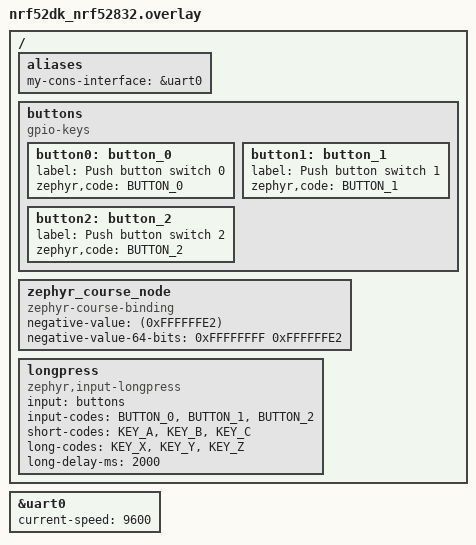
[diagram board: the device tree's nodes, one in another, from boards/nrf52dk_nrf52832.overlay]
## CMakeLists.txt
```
add_subdirectory(
    ${CMAKE_CURRENT_LIST_DIR}/modules/hal_nordic/nrfx
    ${CMAKE_CURRENT_BINARY_DIR}/zephyr_course_nrfx
)

zephyr_syscall_header(${ZEPHYR_MYCOURSEMODULE_MODULE_DIR}/include/blinker.h)

zephyr_library()

zephyr_library_sources(drivers/blinker.c)
zephyr_include_directories(${ZEPHYR_MYCOURSEMODULE_MODULE_DIR}/include)
```

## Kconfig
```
source "Kconfig.zephyr"

menu "Custom Application Configuration"
    
module = ZEPHYR_COURSE
module-str = zephyr_course
source "subsys/logging/Kconfig.template.log_config"

config BOARD
    string # Is invisible since we dont define a prompt
    default "zephyr_course_board"
    help
      Set a custom board name. This value will override the default board name.
config UART_DEVICE_STATUS
    string "UART Status"
    # bool "UART Status"
    # default $(dt_node_str_prop_equals,/soc/uart@40002000,status,okay)
    default $(dt_alias_enabled,my-cons-interface)
    help
      UART device status.

endmenu
```

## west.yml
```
manifest:
  defaults:
    remote: zephyrproject-rtos

  remotes:
    - name: zephyrproject-rtos
      url-base: https://github.com/zephyrproject-rtos

  # Please add items below based on alphabetical order
  projects:
    - name: zephyr
      revision: v4.2.0
      remote: zephyrproject-rtos
      import:
        name-allowlist:
          - cmsis_6
          - hal_nordic

  self:
    path: app
```

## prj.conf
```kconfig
CONFIG_LOG=y
CONFIG_ZEPHYR_COURSE_LOG_LEVEL_ERR=y
# CONFIG_BOARD="zephyr_course_board"
CONFIG_SERIAL=y
CONFIG_UART_ASYNC_API=y

CONFIG_CPP=y
CONFIG_STD_CPP17=y
CONFIG_REQUIRES_FULL_LIBCPP=y
CONFIG_INPUT=y
```

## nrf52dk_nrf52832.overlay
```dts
/ {
    aliases {
        my-cons-interface = &uart0;
    };
};

&uart0 {
    current-speed = <9600>;
};
```

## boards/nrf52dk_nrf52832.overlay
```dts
#include "../dts/bindings/input/input-event-codes.h"

/ {
    aliases {
        my-cons-interface = &uart0;
    };

    // Redefinition of buttons
    buttons: buttons {
		compatible = "gpio-keys";
		button0: button_0 {
			label = "Push button switch 0";
			zephyr,code = <BUTTON_0>;
		};
		button1: button_1 {
			label = "Push button switch 1";
			zephyr,code = <BUTTON_1>;
		};
		button2: button_2 {
			label = "Push button switch 2";
			zephyr,code = <BUTTON_2>;
		};
	};

    zephyr_course_node: zephyr_course_node {
        compatible = "zephyr-course-binding";
        negative-value = <(0xFFFFFFE2)>; // or <(-30)>;
        negative-value-64-bits = <0xFFFFFFFF 0xFFFFFFE2>; // or <(-30)>;
    };

    longpress: longpress {
        compatible = "zephyr,input-longpress";
        input = <&buttons>;
        input-codes = <BUTTON_0>, <BUTTON_1>, <BUTTON_2>;
        short-codes = <KEY_A>, <KEY_B>, <KEY_C>;
        long-codes = <KEY_X>, <KEY_Y>, <KEY_Z>;
        long-delay-ms = <2000>;
    };
};

&uart0 {
    current-speed = <9600>;
};
```

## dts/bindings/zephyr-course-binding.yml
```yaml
description: Custom bindings for zephyr course

compatible: "zephyr-course-binding"

properties:
  negative-value:
    type: int
    required: false

  negative-value-64-bits:
    type: array
    required: false

  leds-number:
    type: array
    required: false
    default: [1, 2, 3]
    description: "Numbers of LEDs to blink"

  intervals:
    type: array
    required: false
    default: [1, 2, 1]
    description: "a period of LED toggling (in seconds)"
  
  interrupt-controller:
    type: phandle
    required: false
    description: "a reference to the device of compatible = gpio,leds"
```

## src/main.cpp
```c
#include <iostream>
#include <string>
#include <zephyr/device.h>
#include <zephyr/drivers/gpio.h>
#include <zephyr/drivers/uart.h>
#include <zephyr/input/input.h>
#include <zephyr/kernel.h>
#include <zephyr/logging/log.h>
#include <zephyr/sys/printk.h>

using namespace std;

LOG_MODULE_REGISTER(my_log_module, CONFIG_ZEPHYR_COURSE_LOG_LEVEL_ERR);

#define MY_CONS_INTERFACE DT_ALIAS(my_cons_interface)
const struct device *uart= DEVICE_DT_GET(MY_CONS_INTERFACE);

#define ZEPHYR_COURSE_NODE DT_NODELABEL(zephyr_course_node)

#define SLEEP_TIME_MS 100

static const struct device *const longpress_dev = DEVICE_DT_GET(
		DT_NODELABEL(longpress));

#define LED0_NODE DT_ALIAS(led0)
#define LED1_NODE DT_ALIAS(led1)
#define LED2_NODE DT_ALIAS(led2)
static const struct gpio_dt_spec led0 = GPIO_DT_SPEC_GET(LED0_NODE, gpios);
static const struct gpio_dt_spec led1 = GPIO_DT_SPEC_GET(LED1_NODE, gpios);
static const struct gpio_dt_spec led2 = GPIO_DT_SPEC_GET(LED2_NODE, gpios);

#define SW0_NODE DT_ALIAS(sw0) 
#define SW1_NODE DT_ALIAS(sw1) 
#define SW2_NODE DT_ALIAS(sw2) 
static const struct gpio_dt_spec button0 = GPIO_DT_SPEC_GET(SW0_NODE, gpios);
static const struct gpio_dt_spec button1 = GPIO_DT_SPEC_GET(SW1_NODE, gpios);
static const struct gpio_dt_spec button2 = GPIO_DT_SPEC_GET(SW2_NODE, gpios);

static void input_event_handler(struct input_event *evt)
{
    // Print event output data
    LOG_ERR("input event: dev=%-16s %3s type=%2x code=%3d value=%d",
		evt->dev ? evt->dev->name : "NULL",
		evt->sync ? "SYN" : "",
		evt->type,
		evt->code,
		evt->value);

    if (evt->value == 1)
    {
        switch (evt->code) {

            // release before two second
            case INPUT_KEY_A:
                gpio_pin_toggle_dt(&led0);
                LOG_ERR("INPUT_KEY_A\n");
                break;
            case INPUT_KEY_B:
                gpio_pin_toggle_dt(&led1);
                LOG_ERR("INPUT_KEY_B\n");
                break;
            case INPUT_KEY_C:
                gpio_pin_toggle_dt(&led2);
                LOG_ERR("INPUT_KEY_C\n");
                break;

            // hold for more than two second
            case INPUT_KEY_X:
                gpio_pin_toggle_dt(&led0);
                LOG_ERR("INPUT_KEY_X\n");
                break;
            case INPUT_KEY_Y:
                gpio_pin_toggle_dt(&led1);
                LOG_ERR("INPUT_KEY_Y\n");
                break;
            case INPUT_KEY_Z:
                gpio_pin_toggle_dt(&led2);
                LOG_ERR("INPUT_KEY_Z\n");
                break;
        }
    }
}
INPUT_CALLBACK_DEFINE(longpress_dev, input_event_handler);

int main(void)
{
    constexpr bool is_native_posix = (CONFIG_BOARD == "native_posix_64");
    if (is_native_posix) {
       LOG_ERR("The application is running on the native_posix_64 host board\n");
    } else {
        LOG_ERR("Running on %s", CONFIG_BOARD);
    }

    // ======================================

    LOG_ERR("LOG_ERR Message: Running on board: %s", CONFIG_BOARD);

    // ======================================

    if (!device_is_ready(uart)){
        printk("UART device not ready\r\n");
        return 1 ;
	}

    if(CONFIG_UART_DEVICE_STATUS == "y"){
        LOG_ERR("UART device is enabled");
        LOG_ERR("Device current-speed: %d", DT_PROP(MY_CONS_INTERFACE, current_speed));
        LOG_ERR("Device status: %s", DT_PROP(MY_CONS_INTERFACE, status));
        LOG_ERR("UART Base Address: 0x%x", DT_REG_ADDR(MY_CONS_INTERFACE));
    }else{
        LOG_ERR("UART device is not enabled");
    }

    // ======================================

    // 32 bits
    int64_t negative_valuee = (int32_t)DT_PROP(ZEPHYR_COURSE_NODE, negative_value);
    LOG_ERR("negative-value prop value: %lld", negative_valuee);

    // 64 bits
    int32_t negative_value_64_bits_high = DT_PROP_BY_IDX(ZEPHYR_COURSE_NODE, negative_value_64_bits, 0);
    uint32_t negative_value_64_bits_low  = DT_PROP_BY_IDX(ZEPHYR_COURSE_NODE, negative_value_64_bits, 1);
    int64_t full_value = (static_cast<int64_t>(negative_value_64_bits_high) << 32) | negative_value_64_bits_low;
    LOG_ERR("Full value (64-bit): %lld", full_value);

    // ======================================

	if (!device_is_ready(button0.port)) {
        LOG_ERR("Port device not ready\r\n");
		return -1;
	}

    gpio_pin_configure_dt(&led0, GPIO_OUTPUT_INACTIVE);
    gpio_pin_configure_dt(&led1, GPIO_OUTPUT_INACTIVE);
    gpio_pin_configure_dt(&led2, GPIO_OUTPUT_INACTIVE);

    gpio_pin_configure_dt(&button0, GPIO_INPUT);
    gpio_pin_configure_dt(&button1, GPIO_INPUT);
    gpio_pin_configure_dt(&button2, GPIO_INPUT);

    while (1) {
        k_msleep(SLEEP_TIME_MS);
    }

    return 0;
}
```

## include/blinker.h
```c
#pragma once

#ifdef __cplusplus
extern "C" {
#endif

#include <zephyr/kernel.h>

typedef int (*blink_on)(const struct device *dev, uint8_t duration);
typedef int (*blink_off)(const struct device *dev);

__subsystem struct blinker_driver_api {
    blink_on on;
    blink_off off;
};

__syscall int custom_blink_on(const struct device *dev, uint8_t duration);
static inline int z_impl_custom_blink_on(const struct device *dev, uint8_t duration)
{
    const struct blinker_driver_api *api = (const struct blinker_driver_api *)dev->api;
    return api->on(dev, duration);
}

__syscall int custom_blink_off(const struct device *dev);
static inline int z_impl_custom_blink_off(const struct device *dev)
{
    const struct blinker_driver_api *api = (const struct blinker_driver_api *)dev->api;
    return api->off(dev);
}

#ifdef __cplusplus
}
#endif

#include <syscalls/blinker.h>
```
